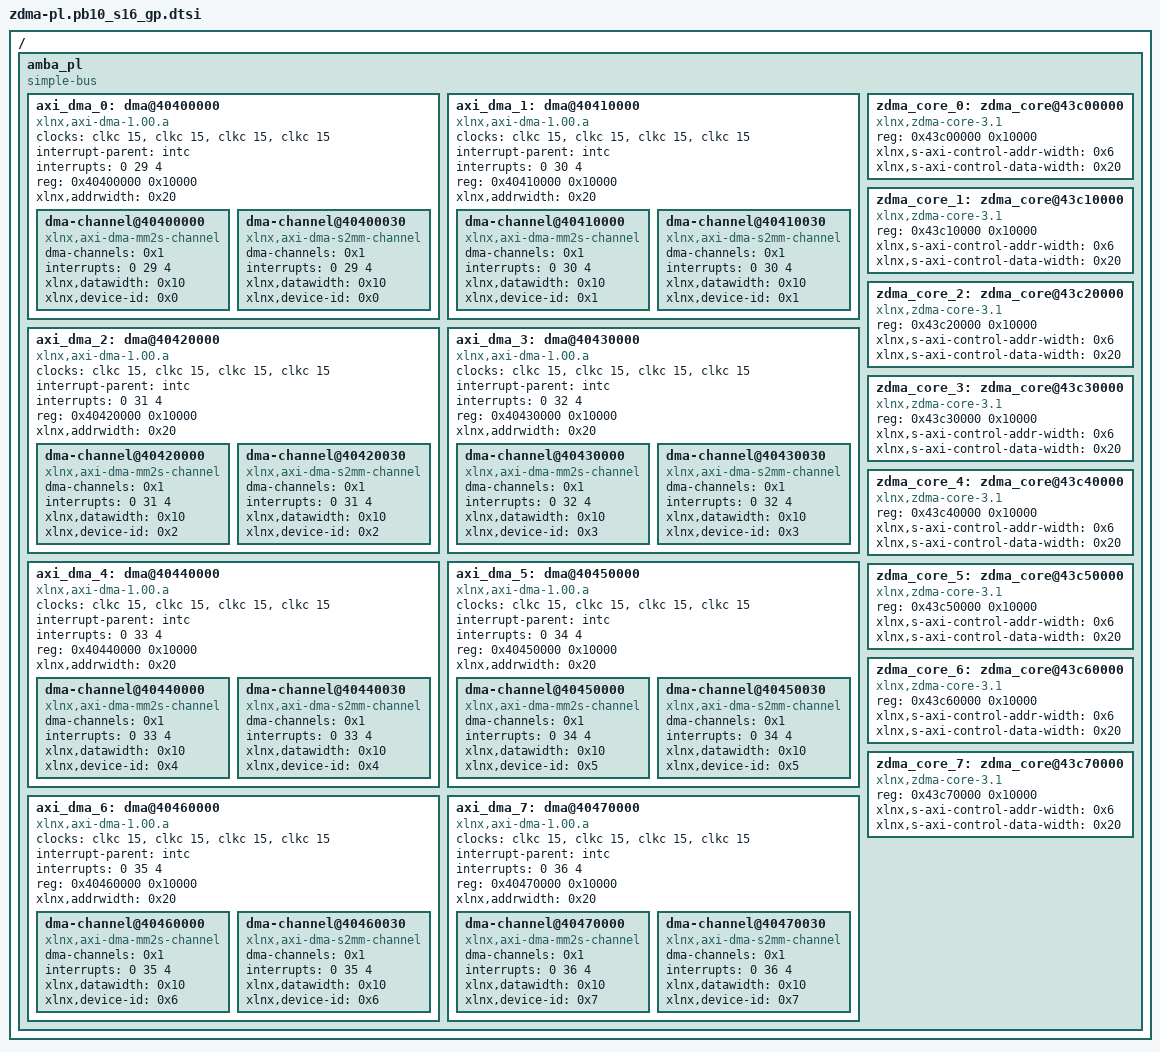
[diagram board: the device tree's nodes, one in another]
/*
 * CAUTION: This file is automatically generated by Xilinx.
 * Version: HSI 2017.2
 * Today is: Sun Dec 17 10:38:21 2017
*/


/ {
	amba_pl: amba_pl {
		#address-cells = <1>;
		#size-cells = <1>;
		compatible = "simple-bus";
		ranges ;
		axi_dma_0: dma@40400000 {
			#dma-cells = <1>;
			clock-names = "s_axi_lite_aclk", "m_axi_sg_aclk", "m_axi_mm2s_aclk", "m_axi_s2mm_aclk";
			clocks = <&clkc 15>, <&clkc 15>, <&clkc 15>, <&clkc 15>;
			compatible = "xlnx,axi-dma-1.00.a";
			interrupt-parent = <&intc>;
			interrupts = <0 29 4>;
			reg = <0x40400000 0x10000>;
			xlnx,addrwidth = <0x20>;
			dma-channel@40400000 {
				compatible = "xlnx,axi-dma-mm2s-channel";
				dma-channels = <0x1>;
				interrupts = <0 29 4>;
				xlnx,datawidth = <0x10>;
				xlnx,device-id = <0x0>;
			};
			dma-channel@40400030 {
				compatible = "xlnx,axi-dma-s2mm-channel";
				dma-channels = <0x1>;
				interrupts = <0 29 4>;
				xlnx,datawidth = <0x10>;
				xlnx,device-id = <0x0>;
			};
		};
		axi_dma_1: dma@40410000 {
			#dma-cells = <1>;
			clock-names = "s_axi_lite_aclk", "m_axi_sg_aclk", "m_axi_mm2s_aclk", "m_axi_s2mm_aclk";
			clocks = <&clkc 15>, <&clkc 15>, <&clkc 15>, <&clkc 15>;
			compatible = "xlnx,axi-dma-1.00.a";
			interrupt-parent = <&intc>;
			interrupts = <0 30 4>;
			reg = <0x40410000 0x10000>;
			xlnx,addrwidth = <0x20>;
			dma-channel@40410000 {
				compatible = "xlnx,axi-dma-mm2s-channel";
				dma-channels = <0x1>;
				interrupts = <0 30 4>;
				xlnx,datawidth = <0x10>;
				xlnx,device-id = <0x1>;
			};
			dma-channel@40410030 {
				compatible = "xlnx,axi-dma-s2mm-channel";
				dma-channels = <0x1>;
				interrupts = <0 30 4>;
				xlnx,datawidth = <0x10>;
				xlnx,device-id = <0x1>;
			};
		};
		axi_dma_2: dma@40420000 {
			#dma-cells = <1>;
			clock-names = "s_axi_lite_aclk", "m_axi_sg_aclk", "m_axi_mm2s_aclk", "m_axi_s2mm_aclk";
			clocks = <&clkc 15>, <&clkc 15>, <&clkc 15>, <&clkc 15>;
			compatible = "xlnx,axi-dma-1.00.a";
			interrupt-parent = <&intc>;
			interrupts = <0 31 4>;
			reg = <0x40420000 0x10000>;
			xlnx,addrwidth = <0x20>;
			dma-channel@40420000 {
				compatible = "xlnx,axi-dma-mm2s-channel";
				dma-channels = <0x1>;
				interrupts = <0 31 4>;
				xlnx,datawidth = <0x10>;
				xlnx,device-id = <0x2>;
			};
			dma-channel@40420030 {
				compatible = "xlnx,axi-dma-s2mm-channel";
				dma-channels = <0x1>;
				interrupts = <0 31 4>;
				xlnx,datawidth = <0x10>;
				xlnx,device-id = <0x2>;
			};
		};
		axi_dma_3: dma@40430000 {
			#dma-cells = <1>;
			clock-names = "s_axi_lite_aclk", "m_axi_sg_aclk", "m_axi_mm2s_aclk", "m_axi_s2mm_aclk";
			clocks = <&clkc 15>, <&clkc 15>, <&clkc 15>, <&clkc 15>;
			compatible = "xlnx,axi-dma-1.00.a";
			interrupt-parent = <&intc>;
			interrupts = <0 32 4>;
			reg = <0x40430000 0x10000>;
			xlnx,addrwidth = <0x20>;
			dma-channel@40430000 {
				compatible = "xlnx,axi-dma-mm2s-channel";
				dma-channels = <0x1>;
				interrupts = <0 32 4>;
				xlnx,datawidth = <0x10>;
				xlnx,device-id = <0x3>;
			};
			dma-channel@40430030 {
				compatible = "xlnx,axi-dma-s2mm-channel";
				dma-channels = <0x1>;
				interrupts = <0 32 4>;
				xlnx,datawidth = <0x10>;
				xlnx,device-id = <0x3>;
			};
		};
		axi_dma_4: dma@40440000 {
			#dma-cells = <1>;
			clock-names = "s_axi_lite_aclk", "m_axi_sg_aclk", "m_axi_mm2s_aclk", "m_axi_s2mm_aclk";
			clocks = <&clkc 15>, <&clkc 15>, <&clkc 15>, <&clkc 15>;
			compatible = "xlnx,axi-dma-1.00.a";
			interrupt-parent = <&intc>;
			interrupts = <0 33 4>;
			reg = <0x40440000 0x10000>;
			xlnx,addrwidth = <0x20>;
			dma-channel@40440000 {
				compatible = "xlnx,axi-dma-mm2s-channel";
				dma-channels = <0x1>;
				interrupts = <0 33 4>;
				xlnx,datawidth = <0x10>;
				xlnx,device-id = <0x4>;
			};
			dma-channel@40440030 {
				compatible = "xlnx,axi-dma-s2mm-channel";
				dma-channels = <0x1>;
				interrupts = <0 33 4>;
				xlnx,datawidth = <0x10>;
				xlnx,device-id = <0x4>;
			};
		};
		axi_dma_5: dma@40450000 {
			#dma-cells = <1>;
			clock-names = "s_axi_lite_aclk", "m_axi_sg_aclk", "m_axi_mm2s_aclk", "m_axi_s2mm_aclk";
			clocks = <&clkc 15>, <&clkc 15>, <&clkc 15>, <&clkc 15>;
			compatible = "xlnx,axi-dma-1.00.a";
			interrupt-parent = <&intc>;
			interrupts = <0 34 4>;
			reg = <0x40450000 0x10000>;
			xlnx,addrwidth = <0x20>;
			dma-channel@40450000 {
				compatible = "xlnx,axi-dma-mm2s-channel";
				dma-channels = <0x1>;
				interrupts = <0 34 4>;
				xlnx,datawidth = <0x10>;
				xlnx,device-id = <0x5>;
			};
			dma-channel@40450030 {
				compatible = "xlnx,axi-dma-s2mm-channel";
				dma-channels = <0x1>;
				interrupts = <0 34 4>;
				xlnx,datawidth = <0x10>;
				xlnx,device-id = <0x5>;
			};
		};
		axi_dma_6: dma@40460000 {
			#dma-cells = <1>;
			clock-names = "s_axi_lite_aclk", "m_axi_sg_aclk", "m_axi_mm2s_aclk", "m_axi_s2mm_aclk";
			clocks = <&clkc 15>, <&clkc 15>, <&clkc 15>, <&clkc 15>;
			compatible = "xlnx,axi-dma-1.00.a";
			interrupt-parent = <&intc>;
			interrupts = <0 35 4>;
			reg = <0x40460000 0x10000>;
			xlnx,addrwidth = <0x20>;
			dma-channel@40460000 {
				compatible = "xlnx,axi-dma-mm2s-channel";
				dma-channels = <0x1>;
				interrupts = <0 35 4>;
				xlnx,datawidth = <0x10>;
				xlnx,device-id = <0x6>;
			};
			dma-channel@40460030 {
				compatible = "xlnx,axi-dma-s2mm-channel";
				dma-channels = <0x1>;
				interrupts = <0 35 4>;
				xlnx,datawidth = <0x10>;
				xlnx,device-id = <0x6>;
			};
		};
		axi_dma_7: dma@40470000 {
			#dma-cells = <1>;
			clock-names = "s_axi_lite_aclk", "m_axi_sg_aclk", "m_axi_mm2s_aclk", "m_axi_s2mm_aclk";
			clocks = <&clkc 15>, <&clkc 15>, <&clkc 15>, <&clkc 15>;
			compatible = "xlnx,axi-dma-1.00.a";
			interrupt-parent = <&intc>;
			interrupts = <0 36 4>;
			reg = <0x40470000 0x10000>;
			xlnx,addrwidth = <0x20>;
			dma-channel@40470000 {
				compatible = "xlnx,axi-dma-mm2s-channel";
				dma-channels = <0x1>;
				interrupts = <0 36 4>;
				xlnx,datawidth = <0x10>;
				xlnx,device-id = <0x7>;
			};
			dma-channel@40470030 {
				compatible = "xlnx,axi-dma-s2mm-channel";
				dma-channels = <0x1>;
				interrupts = <0 36 4>;
				xlnx,datawidth = <0x10>;
				xlnx,device-id = <0x7>;
			};
		};
/*		axi_dma_8: dma@40480000 {
			#dma-cells = <1>;
			clock-names = "s_axi_lite_aclk", "m_axi_sg_aclk", "m_axi_mm2s_aclk", "m_axi_s2mm_aclk";
			clocks = <&clkc 15>, <&clkc 15>, <&clkc 15>, <&clkc 15>;
			compatible = "xlnx,axi-dma-1.00.a";
			interrupt-parent = <&intc>;
			interrupts = <0 52 4>;
			reg = <0x40480000 0x10000>;
			xlnx,addrwidth = <0x20>;
			dma-channel@40480000 {
				compatible = "xlnx,axi-dma-mm2s-channel";
				dma-channels = <0x1>;
				interrupts = <0 52 4>;
				xlnx,datawidth = <0x10>;
				xlnx,device-id = <0x8>;
			};
			dma-channel@40480030 {
				compatible = "xlnx,axi-dma-s2mm-channel";
				dma-channels = <0x1>;
				interrupts = <0 52 4>;
				xlnx,datawidth = <0x10>;
				xlnx,device-id = <0x8>;
			};
		};
		axi_dma_9: dma@40490000 {
			#dma-cells = <1>;
			clock-names = "s_axi_lite_aclk", "m_axi_sg_aclk", "m_axi_mm2s_aclk", "m_axi_s2mm_aclk";
			clocks = <&clkc 15>, <&clkc 15>, <&clkc 15>, <&clkc 15>;
			compatible = "xlnx,axi-dma-1.00.a";
			interrupt-parent = <&intc>;
			interrupts = <0 53 4>;
			reg = <0x40490000 0x10000>;
			xlnx,addrwidth = <0x20>;
			dma-channel@40490000 {
				compatible = "xlnx,axi-dma-mm2s-channel";
				dma-channels = <0x1>;
				interrupts = <0 53 4>;
				xlnx,datawidth = <0x10>;
				xlnx,device-id = <0x9>;
			};
			dma-channel@40490030 {
				compatible = "xlnx,axi-dma-s2mm-channel";
				dma-channels = <0x1>;
				interrupts = <0 53 4>;
				xlnx,datawidth = <0x10>;
				xlnx,device-id = <0x9>;
			};
		};*/
		zdma_core_0: zdma_core@43c00000 {
			compatible = "xlnx,zdma-core-3.1";
			reg = <0x43c00000 0x10000>;
			xlnx,s-axi-control-addr-width = <0x6>;
			xlnx,s-axi-control-data-width = <0x20>;
		};
		zdma_core_1: zdma_core@43c10000 {
			compatible = "xlnx,zdma-core-3.1";
			reg = <0x43c10000 0x10000>;
			xlnx,s-axi-control-addr-width = <0x6>;
			xlnx,s-axi-control-data-width = <0x20>;
		};
		zdma_core_2: zdma_core@43c20000 {
			compatible = "xlnx,zdma-core-3.1";
			reg = <0x43c20000 0x10000>;
			xlnx,s-axi-control-addr-width = <0x6>;
			xlnx,s-axi-control-data-width = <0x20>;
		};
		zdma_core_3: zdma_core@43c30000 {
			compatible = "xlnx,zdma-core-3.1";
			reg = <0x43c30000 0x10000>;
			xlnx,s-axi-control-addr-width = <0x6>;
			xlnx,s-axi-control-data-width = <0x20>;
		};
		zdma_core_4: zdma_core@43c40000 {
			compatible = "xlnx,zdma-core-3.1";
			reg = <0x43c40000 0x10000>;
			xlnx,s-axi-control-addr-width = <0x6>;
			xlnx,s-axi-control-data-width = <0x20>;
		};
		zdma_core_5: zdma_core@43c50000 {
			compatible = "xlnx,zdma-core-3.1";
			reg = <0x43c50000 0x10000>;
			xlnx,s-axi-control-addr-width = <0x6>;
			xlnx,s-axi-control-data-width = <0x20>;
		};
		zdma_core_6: zdma_core@43c60000 {
			compatible = "xlnx,zdma-core-3.1";
			reg = <0x43c60000 0x10000>;
			xlnx,s-axi-control-addr-width = <0x6>;
			xlnx,s-axi-control-data-width = <0x20>;
		};
		zdma_core_7: zdma_core@43c70000 {
			compatible = "xlnx,zdma-core-3.1";
			reg = <0x43c70000 0x10000>;
			xlnx,s-axi-control-addr-width = <0x6>;
			xlnx,s-axi-control-data-width = <0x20>;
		};/*
		zdma_core_8: zdma_core@43c80000 {
			compatible = "xlnx,zdma-core-3.1";
			reg = <0x43c80000 0x10000>;
			xlnx,s-axi-control-addr-width = <0x6>;
			xlnx,s-axi-control-data-width = <0x20>;
		};
		zdma_core_9: zdma_core@43c90000 {
			compatible = "xlnx,zdma-core-3.1";
			reg = <0x43c90000 0x10000>;
			xlnx,s-axi-control-addr-width = <0x6>;
			xlnx,s-axi-control-data-width = <0x20>;
		};*/
	};
};
